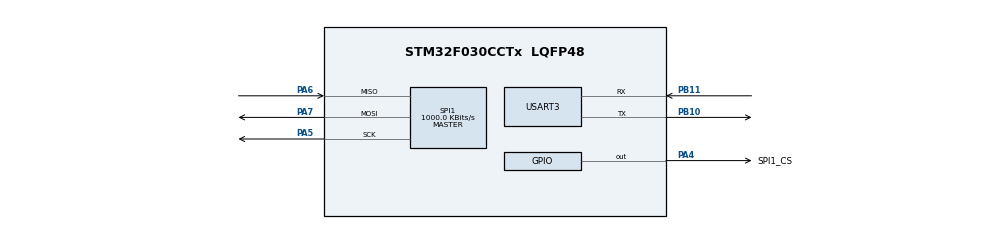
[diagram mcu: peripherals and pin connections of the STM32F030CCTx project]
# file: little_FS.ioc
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Mcu.Family=STM32F0
Mcu.Name=STM32F030CCTx
Mcu.Package=LQFP48
PA4.GPIO_Label=SPI1_CS
PA4.Signal=GPIO_Output
PA5.Mode=Full_Duplex_Master
PA5.Signal=SPI1_SCK
PA6.Mode=Full_Duplex_Master
PA6.Signal=SPI1_MISO
PA7.Mode=Full_Duplex_Master
PA7.Signal=SPI1_MOSI
PB10.Mode=Asynchronous
PB10.Signal=USART3_TX
PB11.Mode=Asynchronous
PB11.Signal=USART3_RX
PC15OSC32_OUT.GPIO_Label=LD1
PC15OSC32_OUT.Signal=GPIO_Output
ProjectManager.HeapSize=0x200
ProjectManager.StackSize=0x400
ProjectManager.TargetToolchain=STM32CubeIDE
SPI1.BaudRatePrescaler=SPI_BAUDRATEPRESCALER_8
SPI1.CalculateBaudRate=1000.0 KBits/s
SPI1.DataSize=SPI_DATASIZE_8BIT
SPI1.Direction=SPI_DIRECTION_2LINES
SPI1.Mode=SPI_MODE_MASTER
SPI1.VirtualType=VM_MASTER
USART3.VirtualMode-Asynchronous=VM_ASYNC
board=custom

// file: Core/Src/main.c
/* USER CODE BEGIN Header */
/**
 ******************************************************************************
 * @file           : main.c
 * @brief          : Main program body
 ******************************************************************************
 * @attention
 *
 * Copyright (c) 2025 STMicroelectronics.
 * All rights reserved.
 *
 * This software is licensed under terms that can be found in the LICENSE file
 * in the root directory of this software component.
 * If no LICENSE file comes with this software, it is provided AS-IS.
 *
 ******************************************************************************
 */
/* USER CODE END Header */
#include "main.h"

/* USER CODE BEGIN Includes */
#include <stdio.h>
#include <stdbool.h>
#include "w25qxx.h"
#include "LFS_wrapper.h"
#include "w25qxx_littlefs.h"
/* USER CODE END Includes */

SPI_HandleTypeDef hspi1;

UART_HandleTypeDef huart3;

void SystemClock_Config(void);
static void MX_GPIO_Init(void);
static void MX_SPI1_Init(void);
static void MX_USART3_UART_Init(void);

/* USER CODE BEGIN 0 */
int _write(int file, char *ptr, int len) {
	HAL_UART_Transmit(&huart3, (const uint8_t*) ptr, len, HAL_MAX_DELAY);
	return len;
}
W25QXX_HandleTypeDef W25Q128_Details = { 0 };
bool initLittle_FS(void);
/* USER CODE END 0 */

int main(void) {

	/* MCU Configuration--------------------------------------------------------*/

	/* Reset of all peripherals, Initializes the Flash interface and the Systick. */
	HAL_Init();

	/* Configure the system clock */
	SystemClock_Config();

	/* Initialize all configured peripherals */
	MX_GPIO_Init();
	MX_SPI1_Init();
	MX_USART3_UART_Init();
	/* USER CODE BEGIN 2 */
	printf("System init \r\n");
	if (!initLittle_FS()) {
		printf("[ ERROR ] Little FS init failed \r\n");
		return false;
	} else {
		printf("File system mounted \r\n");
	}
	readAndPrintStorageDetails();
	listFiles();

	/********* EXAMPLE TEST OF FILE SYSTEM *********/
	const char *data = "Hello, LittleFS!";
	size_t bytes_written;
	if (saveFileIntoFlash("test.txt", data, strlen(data), &bytes_written)) {
		printf("Data written successfully\n");
	}

	size_t file_size;
	if (getFileSize("test.txt", &file_size)) {
		printf("File size: %u bytes\n", file_size);
	}

	char buffer[128] = { 0 };
	size_t bytes_read = 0;
	if (readFilefromFlash("test.txt", file_size, buffer, &bytes_read)) {
		printf("File content: %s\n", buffer);
	}

	const char *append_data = "I should be appended in same line ";
	if (appendDataAtTheEndOfFile("test.txt", append_data, strlen(append_data),
			&bytes_written)) {
		printf("Data appended successfully\n");
	}

	const char *append_data_new = "I should be appended in new line ";
	if (appendDataAtTheEndOfFileWithNewLine("test.txt", append_data_new,
			strlen(append_data), &bytes_written)) {
		printf("Data appended successfully\n");
	}

	if (getFileSize("test.txt", &file_size)) {
		printf("File size: %u bytes\n", file_size);
	}

	memset(buffer, 0, 128);
	bytes_read = 0;
	if (readFilefromFlash("test.txt", sizeof(buffer), buffer, &bytes_read)) {
		printf("File content: %s\n", buffer);
	}
	/* USER CODE END 2 */

	/* Infinite loop */
	while (1) {

	}
}

void SystemClock_Config(void) {
	RCC_OscInitTypeDef RCC_OscInitStruct = { 0 };
	RCC_ClkInitTypeDef RCC_ClkInitStruct = { 0 };

	/** Initializes the RCC Oscillators according to the specified parameters
	 * in the RCC_OscInitTypeDef structure.
	 */
	RCC_OscInitStruct.OscillatorType = RCC_OSCILLATORTYPE_HSI;
	RCC_OscInitStruct.HSIState = RCC_HSI_ON;
	RCC_OscInitStruct.HSICalibrationValue = RCC_HSICALIBRATION_DEFAULT;
	RCC_OscInitStruct.PLL.PLLState = RCC_PLL_NONE;
	if (HAL_RCC_OscConfig(&RCC_OscInitStruct) != HAL_OK) {
		Error_Handler();
	}

	/** Initializes the CPU, AHB and APB buses clocks
	 */
	RCC_ClkInitStruct.ClockType = RCC_CLOCKTYPE_HCLK | RCC_CLOCKTYPE_SYSCLK
			| RCC_CLOCKTYPE_PCLK1;
	RCC_ClkInitStruct.SYSCLKSource = RCC_SYSCLKSOURCE_HSI;
	RCC_ClkInitStruct.AHBCLKDivider = RCC_SYSCLK_DIV1;
	RCC_ClkInitStruct.APB1CLKDivider = RCC_HCLK_DIV1;

	if (HAL_RCC_ClockConfig(&RCC_ClkInitStruct, FLASH_LATENCY_0) != HAL_OK) {
		Error_Handler();
	}
}

static void MX_SPI1_Init(void) {

	/* SPI1 parameter configuration*/
	hspi1.Instance = SPI1;
	hspi1.Init.Mode = SPI_MODE_MASTER;
	hspi1.Init.Direction = SPI_DIRECTION_2LINES;
	hspi1.Init.DataSize = SPI_DATASIZE_8BIT;
	hspi1.Init.CLKPolarity = SPI_POLARITY_LOW;
	hspi1.Init.CLKPhase = SPI_PHASE_1EDGE;
	hspi1.Init.NSS = SPI_NSS_SOFT;
	hspi1.Init.BaudRatePrescaler = SPI_BAUDRATEPRESCALER_8;
	hspi1.Init.FirstBit = SPI_FIRSTBIT_MSB;
	hspi1.Init.TIMode = SPI_TIMODE_DISABLE;
	hspi1.Init.CRCCalculation = SPI_CRCCALCULATION_DISABLE;
	hspi1.Init.CRCPolynomial = 7;
	hspi1.Init.CRCLength = SPI_CRC_LENGTH_DATASIZE;
	hspi1.Init.NSSPMode = SPI_NSS_PULSE_ENABLE;
	if (HAL_SPI_Init(&hspi1) != HAL_OK) {
		Error_Handler();
	}

}

static void MX_USART3_UART_Init(void) {

	huart3.Instance = USART3;
	huart3.Init.BaudRate = 115200;
	huart3.Init.WordLength = UART_WORDLENGTH_8B;
	huart3.Init.StopBits = UART_STOPBITS_1;
	huart3.Init.Parity = UART_PARITY_NONE;
	huart3.Init.Mode = UART_MODE_TX_RX;
	huart3.Init.HwFlowCtl = UART_HWCONTROL_NONE;
	huart3.Init.OverSampling = UART_OVERSAMPLING_16;
	huart3.Init.OneBitSampling = UART_ONE_BIT_SAMPLE_DISABLE;
	huart3.AdvancedInit.AdvFeatureInit = UART_ADVFEATURE_NO_INIT;
	if (HAL_UART_Init(&huart3) != HAL_OK) {
		Error_Handler();
	}

}

static void MX_GPIO_Init(void) {
	GPIO_InitTypeDef GPIO_InitStruct = { 0 };

	/* GPIO Ports Clock Enable */
	__HAL_RCC_GPIOC_CLK_ENABLE();
	__HAL_RCC_GPIOA_CLK_ENABLE();
	__HAL_RCC_GPIOB_CLK_ENABLE();

	/*Configure GPIO pin Output Level */
	HAL_GPIO_WritePin(LD1_GPIO_Port, LD1_Pin, GPIO_PIN_RESET);

	/*Configure GPIO pin Output Level */
	HAL_GPIO_WritePin(SPI1_CS_GPIO_Port, SPI1_CS_Pin, GPIO_PIN_RESET);

	/*Configure GPIO pin : LD1_Pin */
	GPIO_InitStruct.Pin = LD1_Pin;
	GPIO_InitStruct.Mode = GPIO_MODE_OUTPUT_PP;
	GPIO_InitStruct.Pull = GPIO_NOPULL;
	GPIO_InitStruct.Speed = GPIO_SPEED_FREQ_LOW;
	HAL_GPIO_Init(LD1_GPIO_Port, &GPIO_InitStruct);

	/*Configure GPIO pin : SPI1_CS_Pin */
	GPIO_InitStruct.Pin = SPI1_CS_Pin;
	GPIO_InitStruct.Mode = GPIO_MODE_OUTPUT_PP;
	GPIO_InitStruct.Pull = GPIO_NOPULL;
	GPIO_InitStruct.Speed = GPIO_SPEED_FREQ_LOW;
	HAL_GPIO_Init(SPI1_CS_GPIO_Port, &GPIO_InitStruct);

}

/* USER CODE BEGIN 4 */
bool initLittle_FS(void) {
	W25Q128_Details.spiHandle = &hspi1;
	W25Q128_Details.cs_port = SPI1_CS_GPIO_Port;
	W25Q128_Details.cs_pin = SPI1_CS_Pin;
	W25Q128_Details.manufacturer_id = 0XEF;
	W25Q128_Details.device_id = 0X4018;
	W25Q128_Details.block_size = 4096;
	W25Q128_Details.block_count = 4096;
	W25Q128_Details.sector_size = 4096;
	W25Q128_Details.sectors_in_block = 1;
	W25Q128_Details.page_size = 256;
	W25Q128_Details.pages_in_sector = 16;

	w25qxx_littlefs_init(&W25Q128_Details);
	return true;
}
/* USER CODE END 4 */

void Error_Handler(void) {
	__disable_irq();
	while (1) {
	}
}
